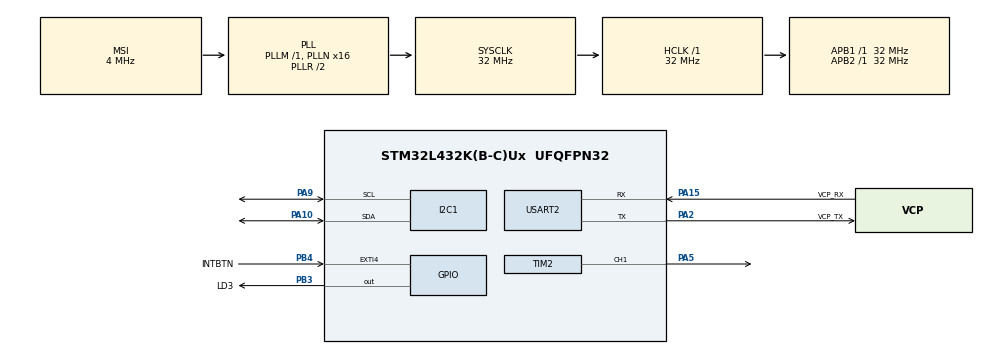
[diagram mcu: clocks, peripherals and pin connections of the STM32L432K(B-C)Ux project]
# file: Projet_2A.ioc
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I2C1.Timing=0x00707CBB
Mcu.Family=STM32L4
Mcu.Name=STM32L432K(B-C)Ux
Mcu.Package=UFQFPN32
NVIC.EXTI4_IRQn=true\:0\:0\:false\:false\:true\:true\:true
NVIC.PriorityGroup=NVIC_PRIORITYGROUP_4
NVIC.TIM1_BRK_TIM15_IRQn=true\:0\:0\:false\:false\:true\:true\:true
NVIC.TIM2_IRQn=true\:0\:0\:false\:false\:true\:true\:true
PA0.GPIO_Label=MCO [High speed clock in]
PA0.Mode=HSE-External-Clock-Source-for-LittleOrca
PA0.Signal=RCC_CK_IN
PA1.Signal=SPI1_SCK
PA10.Mode=I2C
PA10.Signal=I2C1_SDA
PA13\ (JTMS-SWDIO).GPIO_Label=SWDIO
PA13\ (JTMS-SWDIO).Mode=Serial_Wire
PA13\ (JTMS-SWDIO).Signal=SYS_JTMS-SWDIO
PA14\ (JTCK-SWCLK).GPIO_Label=SWCLK
PA14\ (JTCK-SWCLK).Mode=Serial_Wire
PA14\ (JTCK-SWCLK).Signal=SYS_JTCK-SWCLK
PA15\ (JTDI).GPIO_Label=VCP_RX
PA15\ (JTDI).Mode=Asynchronous
PA15\ (JTDI).Signal=USART2_RX
PA2.GPIO_Label=VCP_TX
PA2.Mode=Asynchronous
PA2.Signal=USART2_TX
PA3.Signal=ADCx_IN8
PA5.Signal=S_TIM2_CH1
PA9.Mode=I2C
PA9.Signal=I2C1_SCL
PB3\ (JTDO-TRACESWO).GPIO_Label=LD3
PB3\ (JTDO-TRACESWO).GPIO_Speed=GPIO_SPEED_FREQ_LOW
PB3\ (JTDO-TRACESWO).PinState=GPIO_PIN_RESET
PB3\ (JTDO-TRACESWO).Signal=GPIO_Output
PB4\ (NJTRST).GPIO_Label=INTBTN
PB4\ (NJTRST).Signal=GPXTI4
PC14-OSC32_IN\ (PC14).Mode=LSE-External-Oscillator
PC14-OSC32_IN\ (PC14).Signal=RCC_OSC32_IN
PC15-OSC32_OUT\ (PC15).Mode=LSE-External-Oscillator
PC15-OSC32_OUT\ (PC15).Signal=RCC_OSC32_OUT
ProjectManager.HeapSize=0x200
ProjectManager.StackSize=0x400
ProjectManager.TargetToolchain=STM32CubeIDE
RCC.ADCFreq_Value=32000000
RCC.AHBFreq_Value=32000000
RCC.APB1Freq_Value=32000000
RCC.APB1TimFreq_Value=32000000
RCC.APB2Freq_Value=32000000
RCC.APB2TimFreq_Value=32000000
RCC.CortexFreq_Value=32000000
RCC.HCLKFreq_Value=32000000
RCC.HSE_VALUE=8000000
RCC.HSI16_VALUE=16000000
RCC.HSI48_VALUE=48000000
RCC.HSI_VALUE=16000000
RCC.MSI_VALUE=4000000
RCC.PLLMUL=RCC_PLLMUL_4
RCC.PLLN=16
RCC.PLLSAI1N=16
RCC.SYSCLKFreq_VALUE=32000000
RCC.SYSCLKSource=RCC_SYSCLKSOURCE_PLLCLK
RCC.USBFreq_Value=32000000
RCC.VCOOutputFreq_Value=64000000
SH.ADCx_IN8.0=ADC1_IN8
SH.S_TIM2_CH1.0=TIM2_CH1,PWM Generation1 CH1
TIM15.Period=1000-1
TIM15.Prescaler=32000-1
TIM2.AutoReloadPreload=TIM_AUTORELOAD_PRELOAD_ENABLE
TIM2.Channel-PWM\ Generation1\ CH1=TIM_CHANNEL_1
TIM2.Period=99
TIM2.Prescaler=999
TIM2.Pulse-PWM\ Generation1\ CH1=50
TIM2.TIM_MasterOutputTrigger=TIM_TRGO_RESET
USART2.VirtualMode-Asynchronous=VM_ASYNC
VP_TIM15_VS_ClockSourceINT.Mode=Internal
VP_TIM2_VS_ClockSourceINT.Mode=Internal
VP_TIM2_VS_OPM.Mode=OPM_bit
board=NUCLEO-L432KC

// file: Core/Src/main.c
/* USER CODE BEGIN Header */
/**
 ******************************************************************************
 * @file           : main.c
 * @brief          : Main program body
 ******************************************************************************
 * @attention
 *
 * <h2><center>&copy; Copyright (c) 2021 STMicroelectronics.
 * All rights reserved.</center></h2>
 *
 * This software component is licensed by ST under BSD 3-Clause license,
 * the "License"; You may not use this file except in compliance with the
 * License. You may obtain a copy of the License at:
 *                        opensource.org/licenses/BSD-3-Clause
 *
 ******************************************************************************

 Dernière mise à jour du code : le 15/02/2022
 Obj : récupérer données sur l'IMU 10 DOF

 */
/* USER CODE END Header */
#include "main.h"

/* USER CODE BEGIN Includes */
#include "stdio.h"
#include "urbansensor.h"

/* USER CODE END Includes */

I2C_HandleTypeDef hi2c1;

TIM_HandleTypeDef htim2;
TIM_HandleTypeDef htim15;

UART_HandleTypeDef huart2;

/* USER CODE BEGIN PV */
uint8_t INTBTN = 0;
uint8_t INTTIM15 = 1;
/* USER CODE END PV */

void SystemClock_Config(void);
static void MX_GPIO_Init(void);
static void MX_USART2_UART_Init(void);
static void MX_I2C1_Init(void);
static void MX_TIM2_Init(void);
static void MX_TIM15_Init(void);

int main(void)
{

  /* MCU Configuration--------------------------------------------------------*/

  /* Reset of all peripherals, Initializes the Flash interface and the Systick. */
  HAL_Init();

  /* Configure the system clock */
  SystemClock_Config();

  /* Initialize all configured peripherals */
  MX_GPIO_Init();
  MX_USART2_UART_Init();
  MX_I2C1_Init();
  MX_TIM2_Init();
  MX_TIM15_Init();
  /* USER CODE BEGIN 2 */

  //Fonction qui fait touuuut

  urban_sensor();
  HAL_TIM_PWM_Start(&htim2, TIM_CHANNEL_1);

  /* USER CODE END 2 */

  /* Infinite loop */

}

void SystemClock_Config(void)
{
  RCC_OscInitTypeDef RCC_OscInitStruct = {0};
  RCC_ClkInitTypeDef RCC_ClkInitStruct = {0};

  /** Configure the main internal regulator output voltage
  */
  if (HAL_PWREx_ControlVoltageScaling(PWR_REGULATOR_VOLTAGE_SCALE1) != HAL_OK)
  {
    Error_Handler();
  }
  /** Configure LSE Drive Capability
  */
  HAL_PWR_EnableBkUpAccess();
  __HAL_RCC_LSEDRIVE_CONFIG(RCC_LSEDRIVE_LOW);
  /** Initializes the RCC Oscillators according to the specified parameters
  * in the RCC_OscInitTypeDef structure.
  */
  RCC_OscInitStruct.OscillatorType = RCC_OSCILLATORTYPE_LSE|RCC_OSCILLATORTYPE_MSI;
  RCC_OscInitStruct.LSEState = RCC_LSE_ON;
  RCC_OscInitStruct.MSIState = RCC_MSI_ON;
  RCC_OscInitStruct.MSICalibrationValue = 0;
  RCC_OscInitStruct.MSIClockRange = RCC_MSIRANGE_6;
  RCC_OscInitStruct.PLL.PLLState = RCC_PLL_ON;
  RCC_OscInitStruct.PLL.PLLSource = RCC_PLLSOURCE_MSI;
  RCC_OscInitStruct.PLL.PLLM = 1;
  RCC_OscInitStruct.PLL.PLLN = 16;
  RCC_OscInitStruct.PLL.PLLP = RCC_PLLP_DIV7;
  RCC_OscInitStruct.PLL.PLLQ = RCC_PLLQ_DIV2;
  RCC_OscInitStruct.PLL.PLLR = RCC_PLLR_DIV2;
  if (HAL_RCC_OscConfig(&RCC_OscInitStruct) != HAL_OK)
  {
    Error_Handler();
  }
  /** Initializes the CPU, AHB and APB buses clocks
  */
  RCC_ClkInitStruct.ClockType = RCC_CLOCKTYPE_HCLK|RCC_CLOCKTYPE_SYSCLK
                              |RCC_CLOCKTYPE_PCLK1|RCC_CLOCKTYPE_PCLK2;
  RCC_ClkInitStruct.SYSCLKSource = RCC_SYSCLKSOURCE_PLLCLK;
  RCC_ClkInitStruct.AHBCLKDivider = RCC_SYSCLK_DIV1;
  RCC_ClkInitStruct.APB1CLKDivider = RCC_HCLK_DIV1;
  RCC_ClkInitStruct.APB2CLKDivider = RCC_HCLK_DIV1;

  if (HAL_RCC_ClockConfig(&RCC_ClkInitStruct, FLASH_LATENCY_1) != HAL_OK)
  {
    Error_Handler();
  }
  /** Enable MSI Auto calibration
  */
  HAL_RCCEx_EnableMSIPLLMode();
}

static void MX_I2C1_Init(void)
{

  hi2c1.Instance = I2C1;
  hi2c1.Init.Timing = 0x00707CBB;
  hi2c1.Init.OwnAddress1 = 0;
  hi2c1.Init.AddressingMode = I2C_ADDRESSINGMODE_7BIT;
  hi2c1.Init.DualAddressMode = I2C_DUALADDRESS_DISABLE;
  hi2c1.Init.OwnAddress2 = 0;
  hi2c1.Init.OwnAddress2Masks = I2C_OA2_NOMASK;
  hi2c1.Init.GeneralCallMode = I2C_GENERALCALL_DISABLE;
  hi2c1.Init.NoStretchMode = I2C_NOSTRETCH_DISABLE;
  if (HAL_I2C_Init(&hi2c1) != HAL_OK)
  {
    Error_Handler();
  }
  /** Configure Analogue filter
  */
  if (HAL_I2CEx_ConfigAnalogFilter(&hi2c1, I2C_ANALOGFILTER_ENABLE) != HAL_OK)
  {
    Error_Handler();
  }
  /** Configure Digital filter
  */
  if (HAL_I2CEx_ConfigDigitalFilter(&hi2c1, 0) != HAL_OK)
  {
    Error_Handler();
  }

}

static void MX_TIM2_Init(void)
{

  TIM_ClockConfigTypeDef sClockSourceConfig = {0};
  TIM_MasterConfigTypeDef sMasterConfig = {0};
  TIM_OC_InitTypeDef sConfigOC = {0};

  htim2.Instance = TIM2;
  htim2.Init.Prescaler = 999;
  htim2.Init.CounterMode = TIM_COUNTERMODE_UP;
  htim2.Init.Period = 99;
  htim2.Init.ClockDivision = TIM_CLOCKDIVISION_DIV1;
  htim2.Init.AutoReloadPreload = TIM_AUTORELOAD_PRELOAD_ENABLE;
  if (HAL_TIM_Base_Init(&htim2) != HAL_OK)
  {
    Error_Handler();
  }
  sClockSourceConfig.ClockSource = TIM_CLOCKSOURCE_INTERNAL;
  if (HAL_TIM_ConfigClockSource(&htim2, &sClockSourceConfig) != HAL_OK)
  {
    Error_Handler();
  }
  if (HAL_TIM_PWM_Init(&htim2) != HAL_OK)
  {
    Error_Handler();
  }
  if (HAL_TIM_OnePulse_Init(&htim2, TIM_OPMODE_SINGLE) != HAL_OK)
  {
    Error_Handler();
  }
  sMasterConfig.MasterOutputTrigger = TIM_TRGO_RESET;
  sMasterConfig.MasterSlaveMode = TIM_MASTERSLAVEMODE_DISABLE;
  if (HAL_TIMEx_MasterConfigSynchronization(&htim2, &sMasterConfig) != HAL_OK)
  {
    Error_Handler();
  }
  sConfigOC.OCMode = TIM_OCMODE_PWM1;
  sConfigOC.Pulse = 50;
  sConfigOC.OCPolarity = TIM_OCPOLARITY_HIGH;
  sConfigOC.OCFastMode = TIM_OCFAST_DISABLE;
  if (HAL_TIM_PWM_ConfigChannel(&htim2, &sConfigOC, TIM_CHANNEL_1) != HAL_OK)
  {
    Error_Handler();
  }
  HAL_TIM_MspPostInit(&htim2);

}

static void MX_TIM15_Init(void)
{

  TIM_ClockConfigTypeDef sClockSourceConfig = {0};
  TIM_MasterConfigTypeDef sMasterConfig = {0};

  htim15.Instance = TIM15;
  htim15.Init.Prescaler = 32000-1;
  htim15.Init.CounterMode = TIM_COUNTERMODE_UP;
  htim15.Init.Period = 1000-1;
  htim15.Init.ClockDivision = TIM_CLOCKDIVISION_DIV1;
  htim15.Init.RepetitionCounter = 0;
  htim15.Init.AutoReloadPreload = TIM_AUTORELOAD_PRELOAD_DISABLE;
  if (HAL_TIM_Base_Init(&htim15) != HAL_OK)
  {
    Error_Handler();
  }
  sClockSourceConfig.ClockSource = TIM_CLOCKSOURCE_INTERNAL;
  if (HAL_TIM_ConfigClockSource(&htim15, &sClockSourceConfig) != HAL_OK)
  {
    Error_Handler();
  }
  sMasterConfig.MasterOutputTrigger = TIM_TRGO_RESET;
  sMasterConfig.MasterSlaveMode = TIM_MASTERSLAVEMODE_DISABLE;
  if (HAL_TIMEx_MasterConfigSynchronization(&htim15, &sMasterConfig) != HAL_OK)
  {
    Error_Handler();
  }

}

static void MX_USART2_UART_Init(void)
{

  huart2.Instance = USART2;
  huart2.Init.BaudRate = 115200;
  huart2.Init.WordLength = UART_WORDLENGTH_8B;
  huart2.Init.StopBits = UART_STOPBITS_1;
  huart2.Init.Parity = UART_PARITY_NONE;
  huart2.Init.Mode = UART_MODE_TX_RX;
  huart2.Init.HwFlowCtl = UART_HWCONTROL_NONE;
  huart2.Init.OverSampling = UART_OVERSAMPLING_16;
  huart2.Init.OneBitSampling = UART_ONE_BIT_SAMPLE_DISABLE;
  huart2.AdvancedInit.AdvFeatureInit = UART_ADVFEATURE_NO_INIT;
  if (HAL_UART_Init(&huart2) != HAL_OK)
  {
    Error_Handler();
  }

}

static void MX_GPIO_Init(void)
{
  GPIO_InitTypeDef GPIO_InitStruct = {0};

  /* GPIO Ports Clock Enable */
  __HAL_RCC_GPIOC_CLK_ENABLE();
  __HAL_RCC_GPIOA_CLK_ENABLE();
  __HAL_RCC_GPIOB_CLK_ENABLE();

  /*Configure GPIO pin Output Level */
  HAL_GPIO_WritePin(LD3_GPIO_Port, LD3_Pin, GPIO_PIN_RESET);

  /*Configure GPIO pin : PA1 */
  GPIO_InitStruct.Pin = GPIO_PIN_1;
  GPIO_InitStruct.Mode = GPIO_MODE_AF_PP;
  GPIO_InitStruct.Pull = GPIO_NOPULL;
  GPIO_InitStruct.Speed = GPIO_SPEED_FREQ_VERY_HIGH;
  GPIO_InitStruct.Alternate = GPIO_AF5_SPI1;
  HAL_GPIO_Init(GPIOA, &GPIO_InitStruct);

  /*Configure GPIO pin : PA3 */
  GPIO_InitStruct.Pin = GPIO_PIN_3;
  GPIO_InitStruct.Mode = GPIO_MODE_ANALOG_ADC_CONTROL;
  GPIO_InitStruct.Pull = GPIO_NOPULL;
  HAL_GPIO_Init(GPIOA, &GPIO_InitStruct);

  /*Configure GPIO pin : LD3_Pin */
  GPIO_InitStruct.Pin = LD3_Pin;
  GPIO_InitStruct.Mode = GPIO_MODE_OUTPUT_PP;
  GPIO_InitStruct.Pull = GPIO_NOPULL;
  GPIO_InitStruct.Speed = GPIO_SPEED_FREQ_LOW;
  HAL_GPIO_Init(LD3_GPIO_Port, &GPIO_InitStruct);

  /*Configure GPIO pin : INTBTN_Pin */
  GPIO_InitStruct.Pin = INTBTN_Pin;
  GPIO_InitStruct.Mode = GPIO_MODE_IT_RISING;
  GPIO_InitStruct.Pull = GPIO_NOPULL;
  HAL_GPIO_Init(INTBTN_GPIO_Port, &GPIO_InitStruct);

  /* EXTI interrupt init*/
  HAL_NVIC_SetPriority(EXTI4_IRQn, 0, 0);
  HAL_NVIC_EnableIRQ(EXTI4_IRQn);

}

/* USER CODE BEGIN 4 */
void HAL_GPIO_EXTI_Callback(uint16_t GPIO_Pin){
	INTBTN = 1;
}
/* USER CODE END 4 */

void Error_Handler(void)
{
	__disable_irq();
	while (1) {
	}
}

/************************ (C) COPYRIGHT STMicroelectronics *****END OF FILE****/
